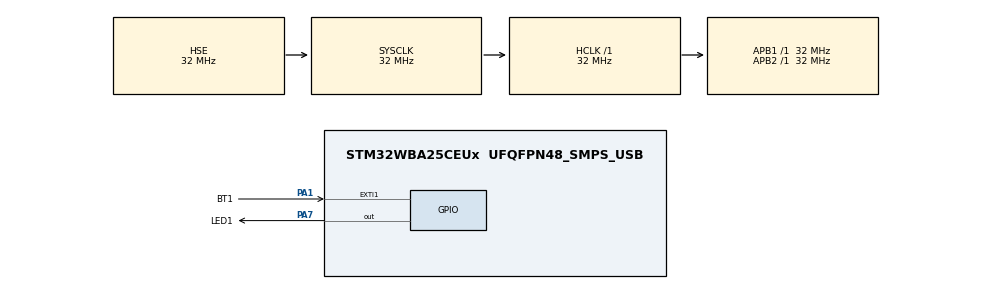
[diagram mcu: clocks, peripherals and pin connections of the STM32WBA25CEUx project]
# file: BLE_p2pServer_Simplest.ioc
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CORTEX_M33_NS.userName=CORTEX_M33
Mcu.Family=STM32WBA
Mcu.Name=STM32WBA25CEUx
Mcu.Package=UFQFPN48_SMPS_USB
NVIC.EXTI1_IRQn=true\:0\:0\:false\:false\:true\:true\:true\:true
NVIC.PKA_IRQn=true\:7\:0\:true\:false\:true\:true\:true\:true
NVIC.PriorityGroup=NVIC_PRIORITYGROUP_4
NVIC.RADIO_IRQn=true\:0\:0\:true\:false\:true\:true\:false\:true
NVIC.RCC_IRQn=true\:1\:0\:false\:false\:true\:false\:false\:true
NVIC.RTC_IRQn=true\:4\:0\:false\:false\:true\:false\:true\:true
NVIC.WKUP_IRQn=true\:5\:0\:true\:false\:true\:true\:true\:true
OSC_IN.Mode=HSE-External-Oscillator
OSC_IN.Signal=RCC_OSC_IN
OSC_OUT.Mode=HSE-External-Oscillator
OSC_OUT.Signal=RCC_OSC_OUT
PA1.GPIO_Label=BT1
PA1.GPIO_ModeDefaultEXTI=GPIO_MODE_IT_FALLING
PA1.GPIO_PuPd=GPIO_PULLUP
PA1.Signal=GPXTI1
PA12.Signal=USART1_RX
PA13\ (JTMS/SWDIO).Mode=Serial_Wire
PA13\ (JTMS/SWDIO).Signal=DEBUG_JTMS-SWDIO
PA14\ (JTCK/SWCLK).Mode=Serial_Wire
PA14\ (JTCK/SWCLK).Signal=DEBUG_JTCK-SWCLK
PA6.Signal=USART1_TX
PA7.GPIO_Label=LED1
PA7.Signal=GPIO_Output
PC14-OSC32_IN.Mode=LSE-External-Oscillator
PC14-OSC32_IN.Signal=RCC_OSC32_IN
PC15-OSC32_OUT.Mode=LSE-External-Oscillator
PC15-OSC32_OUT.Signal=RCC_OSC32_OUT
PWR.pwrPrivilege=PWR_PRIVILEGE_NO
ProjectManager.HeapSize=0x3000
ProjectManager.StackSize=0x1000
ProjectManager.TargetToolchain=EWARM V9.60
RCC.ADCFreq_Value=32000000
RCC.AHBCLKDivider=RCC_SYSCLK_DIV1
RCC.AHBFreq_Value=32000000
RCC.APB1Freq_Value=32000000
RCC.APB1TimFreq_Value=32000000
RCC.APB2Freq_Value=32000000
RCC.APB2TimFreq_Value=32000000
RCC.CortexCLockSelectionVirtual=RCC_SYSTICKCLKSOURCE_LSE
RCC.CortexFreq_Value=32768
RCC.HCLKFreq_Value=32000000
RCC.HSE_VALUE=32000000
RCC.HSI_VALUE=16000000
RCC.LSI1_VALUE=32000
RCC.LSI2_VALUE=32000
RCC.PLLFRACN=0
RCC.PLLN=8
RCC.PREFETCH_ENABLE=1
RCC.PWR_Regulator_Voltage_Scale=PWR_REGULATOR_VOLTAGE_SCALE1
RCC.RCC_MCODiv=RCC_MCODIV_16
RCC.RSTClockSelectionVirtual=RCC_RADIOSTCLKSOURCE_LSE
RCC.RTCClockSelection=RCC_RTCCLKSOURCE_LSE
RCC.SYSCLKFreq_VALUE=32000000
RCC.SYSCLKSourceVirtual=RCC_SYSCLKSOURCE_HSE
RCC.SupplySource=PWR_SMPS_SUPPLY
RCC.USART1CLockSelectionVirtual=RCC_USART1CLKSOURCE_HSI
RCC.VCOOutputFreq_Value=128000000
RTC.Alarm-Alarm\ A=RTC_ALARM_A
RTC.AsynchPrediv=31
RTC.BinMode=RTC_BINARY_ONLY
STM32_WPAN.AD_TYPE_COMPLETE_LOCAL_NAME=p2pS_XX
STM32_WPAN.AD_TYPE_COMPLETE_LOCAL_NAME_LENGTH=8
STM32_WPAN.AD_TYPE_MANUFACTURER_DATA_NBR=12
STM32_WPAN.BLE_OPTIONS_APPEARANCE_WRITABLE=0
STM32_WPAN.BLE_OPTIONS_DEV_NAME_READ_ONLY=0
STM32_WPAN.BLE_OPTIONS_NO_SVC_CHANGE_DESC=0
STM32_WPAN.BLE_OPTIONS_POWER_CLASS_1=0
STM32_WPAN.BLE_OPTIONS_REDUCED_DB_IN_NVM=BLE_OPTIONS_REDUCED_DB_IN_NVM
STM32_WPAN.BLE_STACK_TYPE=BLE_STACK_TYPE_PO
STM32_WPAN.CFG_BD_ADDRESS=0x000000000000
STM32_WPAN.CFG_BLE_ATT_MTU_MAX=251
STM32_WPAN.CFG_BLE_NUM_GATT_ATTRIBUTES=20
STM32_WPAN.CFG_BLE_NUM_GATT_SERVICES=3
STM32_WPAN.CFG_BLE_NUM_LINK=2
STM32_WPAN.CFG_BONDING_MODE=0
STM32_WPAN.CFG_GAP_DEVICE_NAME=Peer to Peer Server
STM32_WPAN.CFG_LOG_SUPPORTED=0
STM32_WPAN.CFG_LOG_VERBOSE_LEVEL=LOG_VERBOSE_INFO
STM32_WPAN.CFG_LPM_LEVEL=0
STM32_WPAN.CFG_LSCLK_LSE=0
STM32_WPAN.CFG_MM_POOL_SIZE=4000
STM32_WPAN.CFG_RF_TX_POWER_TABLE_ID=3
STM32_WPAN.CFG_RT_DEBUG_GPIO_MODULE=0
STM32_WPAN.CFG_TX_POWER=(0x19) /* 0x19 <\=> -0.3 dBm */
STM32_WPAN.INCLUDE_AD_TYPE_COMPLETE_LOCAL_NAME=1
STM32_WPAN.INCLUDE_AD_TYPE_MANUFACTURER_SPECIFIC_DATA=1
STM32_WPAN.NUMBER_OF_SERVICES=1
STM32_WPAN.RADIO_INTR_PRIO_LOW=5
STM32_WPAN.RADIO_SW_LOW_INTR_NUM=HASH_IRQn
STM32_WPAN.SNVMA_POLY_CRC16=1DB7
STM32_WPAN.STATIC_RANDOM_ADDRESS=0xABCDABCDABCD
STM32_WPAN.USE_FLASH_MANAGER=0
STM32_WPAN.USE_SNVMA_NVM=0
VP_AES_VS_AES.Mode=AES_Activate
VP_CORTEX_M33_NS_VS_Ext.Mode=External_Mode
VP_ICACHE_VS_ICACHE.Mode=DirectMappedCache
VP_PKA_VS_PKA.Mode=PKA_Activate
VP_PWR_VS_SECSignals.Mode=Security/Privilege
VP_RF_VS_RF.Mode=RF_Activate
VP_RNG_VS_RNG.Mode=RNG_Activate
VP_RTC_VS_RTC_Activate.Mode=RTC_Enabled
VP_RTC_VS_RTC_Alarm_A_Intern.Mode=Alarm A
VP_RTC_VS_RTC_Calendar.Mode=RTC_Calendar
VP_STM32_WPAN_VS_BLE_HOST_SIMPLE.Mode=BLE_Simplest
board=custom

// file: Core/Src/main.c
/* USER CODE BEGIN Header */
/**
  ******************************************************************************
  * @file           : main.c
  * @brief          : Main program body
  ******************************************************************************
  * @attention
  *
  * Copyright (c) 2026 STMicroelectronics.
  * All rights reserved.
  *
  * This software is licensed under terms that can be found in the LICENSE file
  * in the root directory of this software component.
  * If no LICENSE file comes with this software, it is provided AS-IS.
  *
  ******************************************************************************
  */
/* USER CODE END Header */
#include "main.h"

/* USER CODE BEGIN Includes */
#include "stdio.h"

/* USER CODE END Includes */

CRYP_HandleTypeDef hcryp;
__ALIGN_BEGIN static const uint32_t pKeyAES[4] __ALIGN_END = {
                            0x00000000,0x00000000,0x00000000,0x00000000};

RNG_HandleTypeDef hrng;

RTC_HandleTypeDef hrtc;

void SystemClock_Config(void);
void PeriphCommonClock_Config(void);
static void SystemPower_Config(void);
static void MX_RNG_Init(void);
static void MX_PKA_Init(void);
static void MX_AES_Init(void);

int main(void)
{

  /* MCU Configuration--------------------------------------------------------*/

  /* Reset of all peripherals, Initializes the Flash interface and the Systick. */
  HAL_Init();
  /* Config code for STM32_WPAN (HSE Tuning must be done before system clock configuration) */
  MX_APPE_Config();

  /* Configure the system clock */
  SystemClock_Config();

  /* Configure the peripherals common clocks */
  PeriphCommonClock_Config();

  /* Configure the System Power */
  SystemPower_Config();

  /* Initialize all configured peripherals */
  MX_GPIO_Init();
  MX_RTC_Init();
  MX_ICACHE_Init();
  MX_RNG_Init();
  MX_PKA_Init();
  MX_AES_Init();

  /* Init code for STM32_WPAN */
  MX_APPE_Init(NULL);

  /* Infinite loop */
  while (1)
  {
    MX_APPE_Process();

  }
}

void SystemClock_Config(void)
{
  RCC_OscInitTypeDef RCC_OscInitStruct = {0};
  RCC_ClkInitTypeDef RCC_ClkInitStruct = {0};

  /** Supply configuration update enable
  */
  HAL_PWREx_ConfigSupply(PWR_SMPS_SUPPLY);

  /** Configure the main internal regulator output voltage
  */
  if (HAL_PWREx_ControlVoltageScaling(PWR_REGULATOR_VOLTAGE_SCALE1) != HAL_OK)
  {
    Error_Handler();
  }

  /** Configure LSE Drive Capability
  */
  HAL_PWR_EnableBkUpAccess();
  __HAL_RCC_LSEDRIVE_CONFIG(RCC_LSEDRIVE_MEDIUMLOW);

  /** Initializes the CPU, AHB and APB busses clocks
  */
  RCC_OscInitStruct.OscillatorType = RCC_OSCILLATORTYPE_HSI|RCC_OSCILLATORTYPE_HSE
                              |RCC_OSCILLATORTYPE_LSE;
  RCC_OscInitStruct.HSEState = RCC_HSE_ON;
  RCC_OscInitStruct.HSEDiv = RCC_HSE_DIV1;
  RCC_OscInitStruct.LSEState = RCC_LSE_ON;
  RCC_OscInitStruct.HSIState = RCC_HSI_ON;
  RCC_OscInitStruct.HSICalibrationValue = RCC_HSICALIBRATION_DEFAULT;
  RCC_OscInitStruct.PLL1.PLLState = RCC_PLL_NONE;
  if (HAL_RCC_OscConfig(&RCC_OscInitStruct) != HAL_OK)
  {
    Error_Handler();
  }

  /** Initializes the CPU, AHB and APB busses clocks
  */
  RCC_ClkInitStruct.ClockType = RCC_CLOCKTYPE_HCLK|RCC_CLOCKTYPE_SYSCLK
                              |RCC_CLOCKTYPE_PCLK1|RCC_CLOCKTYPE_PCLK2
                              |RCC_CLOCKTYPE_PCLK7|RCC_CLOCKTYPE_HCLK5;
  RCC_ClkInitStruct.SYSCLKSource = RCC_SYSCLKSOURCE_HSE;
  RCC_ClkInitStruct.AHBCLKDivider = RCC_SYSCLK_DIV1;
  RCC_ClkInitStruct.APB1CLKDivider = RCC_HCLK_DIV1;
  RCC_ClkInitStruct.APB2CLKDivider = RCC_HCLK_DIV1;
  RCC_ClkInitStruct.APB7CLKDivider = RCC_HCLK_DIV1;
  RCC_ClkInitStruct.AHB5_PLL1_CLKDivider = RCC_SYSCLK_PLL1_DIV1;
  RCC_ClkInitStruct.AHB5_HSEHSI_CLKDivider = RCC_SYSCLK_HSEHSI_DIV1;

  if (HAL_RCC_ClockConfig(&RCC_ClkInitStruct, FLASH_LATENCY_0) != HAL_OK)
  {
    Error_Handler();
  }

   /* Select SysTick source clock */
  HAL_SYSTICK_CLKSourceConfig(SYSTICK_CLKSOURCE_LSE);

   /* Re-Initialize Tick with new clock source */
  if (HAL_InitTick(TICK_INT_PRIORITY) != HAL_OK)
  {
    Error_Handler();
  }
}

void PeriphCommonClock_Config(void)
{
  RCC_PeriphCLKInitTypeDef PeriphClkInit = {0};

  /** Initializes the peripherals clock
  */
  PeriphClkInit.PeriphClockSelection = RCC_PERIPHCLK_RADIOST;
  PeriphClkInit.RadioSlpTimClockSelection = RCC_RADIOSTCLKSOURCE_LSE;
  if (HAL_RCCEx_PeriphCLKConfig(&PeriphClkInit) != HAL_OK)
  {
    Error_Handler();
  }
}

/**
  * @brief Power Configuration
  * @retval None
  */
static void SystemPower_Config(void)
{
  /* WKUP_IRQn interrupt configuration */
  HAL_NVIC_SetPriority(WKUP_IRQn, 5, 0);
  HAL_NVIC_EnableIRQ(WKUP_IRQn);
}

static void MX_AES_Init(void)
{

  hcryp.Instance = AES;
  hcryp.Init.DataType = CRYP_NO_SWAP;
  hcryp.Init.KeySize = CRYP_KEYSIZE_128B;
  hcryp.Init.pKey = (uint32_t *)pKeyAES;
  hcryp.Init.Algorithm = CRYP_AES_ECB;
  hcryp.Init.DataWidthUnit = CRYP_DATAWIDTHUNIT_WORD;
  hcryp.Init.HeaderWidthUnit = CRYP_HEADERWIDTHUNIT_WORD;
  hcryp.Init.KeyIVConfigSkip = CRYP_KEYIVCONFIG_ALWAYS;
  if (HAL_CRYP_Init(&hcryp) != HAL_OK)
  {
    Error_Handler();
  }

}

void MX_ICACHE_Init(void)
{

  /** Enable instruction cache in 1-way (direct mapped cache)
  */
  LL_ICACHE_SetMode(LL_ICACHE_1WAY);
  LL_ICACHE_Enable();

}

static void MX_PKA_Init(void)
{

  /* Peripheral clock enable */
  LL_AHB2_GRP1_EnableClock(LL_AHB2_GRP1_PERIPH_PKA);

  /* PKA interrupt Init */
  NVIC_SetPriority(PKA_IRQn, NVIC_EncodePriority(NVIC_GetPriorityGrouping(),7, 0));
  NVIC_EnableIRQ(PKA_IRQn);

  LL_PKA_Enable(PKA);

}

static void MX_RNG_Init(void)
{

  hrng.Instance = RNG;
  hrng.Init.ClockErrorDetection = RNG_CED_DISABLE;
  if (HAL_RNG_Init(&hrng) != HAL_OK)
  {
    Error_Handler();
  }

}

void MX_RTC_Init(void)
{

  RTC_PrivilegeStateTypeDef privilegeState = {0};
  RTC_AlarmTypeDef sAlarm = {0};

  /** Initialize RTC Only
  */
  hrtc.Instance = RTC;
  hrtc.Init.AsynchPrediv = 31;
  hrtc.Init.OutPut = RTC_OUTPUT_DISABLE;
  hrtc.Init.OutPutRemap = RTC_OUTPUT_REMAP_NONE;
  hrtc.Init.OutPutPolarity = RTC_OUTPUT_POLARITY_HIGH;
  hrtc.Init.OutPutType = RTC_OUTPUT_TYPE_OPENDRAIN;
  hrtc.Init.OutPutPullUp = RTC_OUTPUT_PULLUP_NONE;
  hrtc.Init.BinMode = RTC_BINARY_ONLY;
  if (HAL_RTC_Init(&hrtc) != HAL_OK)
  {
    Error_Handler();
  }
  privilegeState.rtcPrivilegeFull = RTC_PRIVILEGE_FULL_NO;
  privilegeState.backupRegisterPrivZone = RTC_PRIVILEGE_BKUP_ZONE_NONE;
  privilegeState.backupRegisterStartZone2 = RTC_BKP_DR0;
  privilegeState.backupRegisterStartZone3 = RTC_BKP_DR0;
  if (HAL_RTCEx_PrivilegeModeSet(&hrtc, &privilegeState) != HAL_OK)
  {
    Error_Handler();
  }

  /** Initialize RTC and set the Time and Date
  */
  if (HAL_RTCEx_SetSSRU_IT(&hrtc) != HAL_OK)
  {
    Error_Handler();
  }

  /** Enable the Alarm A
  */
  sAlarm.BinaryAutoClr = RTC_ALARMSUBSECONDBIN_AUTOCLR_NO;
  sAlarm.AlarmTime.SubSeconds = 0x0;
  sAlarm.AlarmMask = RTC_ALARMMASK_NONE;
  sAlarm.AlarmSubSecondMask = RTC_ALARMSUBSECONDBINMASK_NONE;
  sAlarm.Alarm = RTC_ALARM_A;
  sAlarm.FlagAutoClr = ALARM_FLAG_AUTOCLR_DISABLE;
  if (HAL_RTC_SetAlarm_IT(&hrtc, &sAlarm, RTC_FORMAT_BCD) != HAL_OK)
  {
    Error_Handler();
  }

}

void MX_GPIO_Init(void)
{
  LL_EXTI_InitTypeDef EXTI_InitStruct = {0};
  LL_GPIO_InitTypeDef GPIO_InitStruct = {0};

  /* GPIO Ports Clock Enable */
  LL_AHB2_GRP1_EnableClock(LL_AHB2_GRP1_PERIPH_GPIOA);
  LL_AHB2_GRP1_EnableClock(LL_AHB2_GRP1_PERIPH_GPIOC);

  /**/
  LL_GPIO_ResetOutputPin(LED1_GPIO_Port, LED1_Pin);

  /**/
  GPIO_InitStruct.Pin = LED1_Pin;
  GPIO_InitStruct.Mode = LL_GPIO_MODE_OUTPUT;
  GPIO_InitStruct.Speed = LL_GPIO_SPEED_FREQ_LOW;
  GPIO_InitStruct.OutputType = LL_GPIO_OUTPUT_PUSHPULL;
  GPIO_InitStruct.Pull = LL_GPIO_PULL_NO;
  LL_GPIO_Init(LED1_GPIO_Port, &GPIO_InitStruct);

  /**/
  GPIO_InitStruct.Pin = LL_GPIO_PIN_6;
  GPIO_InitStruct.Mode = LL_GPIO_MODE_ALTERNATE;
  GPIO_InitStruct.Speed = LL_GPIO_SPEED_FREQ_LOW;
  GPIO_InitStruct.OutputType = LL_GPIO_OUTPUT_PUSHPULL;
  GPIO_InitStruct.Pull = LL_GPIO_PULL_NO;
  GPIO_InitStruct.Alternate = GPIO_AF10_USART1;
  LL_GPIO_Init(GPIOA, &GPIO_InitStruct);

  /**/
  GPIO_InitStruct.Pin = LL_GPIO_PIN_12;
  GPIO_InitStruct.Mode = LL_GPIO_MODE_ALTERNATE;
  GPIO_InitStruct.Speed = LL_GPIO_SPEED_FREQ_LOW;
  GPIO_InitStruct.OutputType = LL_GPIO_OUTPUT_PUSHPULL;
  GPIO_InitStruct.Pull = LL_GPIO_PULL_NO;
  GPIO_InitStruct.Alternate = LL_GPIO_AF_7;
  LL_GPIO_Init(GPIOA, &GPIO_InitStruct);

  /**/
  LL_EXTI_SetEXTISource(LL_EXTI_CONFIG_PORTA, LL_EXTI_CONFIG_LINE1);

  /**/
  EXTI_InitStruct.Line_0_31 = LL_EXTI_LINE_1;
  EXTI_InitStruct.LineCommand = ENABLE;
  EXTI_InitStruct.Mode = LL_EXTI_MODE_IT;
  EXTI_InitStruct.Trigger = LL_EXTI_TRIGGER_FALLING;
  LL_EXTI_Init(&EXTI_InitStruct);

  /**/
  LL_GPIO_SetPinPull(BT1_GPIO_Port, BT1_Pin, LL_GPIO_PULL_UP);

  /**/
  LL_GPIO_SetPinMode(BT1_GPIO_Port, BT1_Pin, LL_GPIO_MODE_INPUT);

  /* EXTI interrupt init*/
  NVIC_SetPriority(EXTI1_IRQn, NVIC_EncodePriority(NVIC_GetPriorityGrouping(),0, 0));
  NVIC_EnableIRQ(EXTI1_IRQn);

  /* USER CODE BEGIN MX_GPIO_Init_2 */
  HAL_GPIO_WritePin(LED1_GPIO_Port, LED1_Pin, GPIO_PIN_SET);

  /* USER CODE END MX_GPIO_Init_2 */
}

void Error_Handler(void)
{
  __disable_irq();
  while (1)
  {
  }
}
